AUTOSAR XML (schema 4-2-2)
package /ARPackage_0
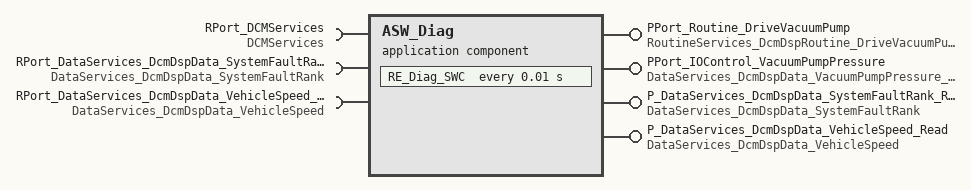
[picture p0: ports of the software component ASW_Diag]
  application sw component type ASW_Diag
    provide port PPort_Routine_DriveVacuumPump: provided-interface=RoutineServices_DcmDspRoutine_DriveVacuumPump
    require port RPort_DCMServices: required-interface=DCMServices
    provide port PPort_IOControl_VacuumPumpPressure: provided-interface=DataServices_DcmDspData_VacuumPumpPressure_1100
    provide port P_DataServices_DcmDspData_SystemFaultRank_Read: provided-interface=DataServices_DcmDspData_SystemFaultRank
    provide port P_DataServices_DcmDspData_VehicleSpeed_Read: provided-interface=DataServices_DcmDspData_VehicleSpeed
    require port RPort_DataServices_DcmDspData_SystemFaultRank_Write: required-interface=DataServices_DcmDspData_SystemFaultRank
    require port RPort_DataServices_DcmDspData_VehicleSpeed_Write: required-interface=DataServices_DcmDspData_VehicleSpeed
    behavior IB_Diag_SWC: data-type-mapping=[DTS_DcmDiagnosticSessionControl, ComMModeMapping, DTS_DcmEcuReset]
      timing event TE_Diag_SWC: start-on-event=RE_Diag_SWC, period=0.01
      8 x operation invoked event:
        OIE_IOControl_VacuumPumpPressure_ReadData: start-on-event=Diag_IOControl_VacuumPumpPressure_ReadData, operation=PPort_IOControl_VacuumPumpPressure.ReadData
        OIE_IOControl_VacuumPumpPressure_returnControlToECU: start-on-event=Diag_IOControl_VacuumPumpPressure_returnControlToECU, operation=PPort_IOControl_VacuumPumpPressure.ReturnControlToECU
        OIE_IOControl_VacuumPumpPressure_resetToDefault: start-on-event=Diag_IOControl_VacuumPumpPressure_resetToDefault, operation=PPort_IOControl_VacuumPumpPressure.ResetToDefault
        OIE_IOControl_VacuumPumpPressure_freezeCurrentState: start-on-event=Diag_IOControl_VacuumPumpPressure_freezeCurrentState, operation=PPort_IOControl_VacuumPumpPressure.FreezeCurrentState
        OIE_IOControl_VacuumPumpPressure_shortTermAdjustment: start-on-event=Diag_IOControl_VacuumPumpPressure_shortTermAdjustment, operation=PPort_IOControl_VacuumPumpPressure.ShortTermAdjustment
        OIE_RoutineServices_DriveVacuumPump_Start: start-on-event=Diag_RoutineServices_DriveVacuumPump_Start, operation=PPort_Routine_DriveVacuumPump.Start
        OIE_RoutineServices_DriveVacuumPump_Stop: start-on-event=Diag_RoutineServices_DriveVacuumPump_Stop, operation=PPort_Routine_DriveVacuumPump.Stop
        OIE_RoutineServices_DriveVacuumPump_RequestRoutineResults: start-on-event=Diag_RoutineServices_DriveVacuumPump_RequestRoutineResults, operation=PPort_Routine_DriveVacuumPump.RequestResults
      9 x runnable:
        RE_Diag_SWC: symbol=RE_Diag_SWC_func
          data-receive-point-by-arguments:
            access DcmDspData_SystemFaultRank_Read: accessed-variable=RPort_DataServices_DcmDspData_SystemFaultRank_Write.Data
            access DcmDspData_VehicleSpeed_Read: accessed-variable=RPort_DataServices_DcmDspData_VehicleSpeed_Write.Data
          data-send-points:
            access DcmDspData_SystemFaultRank_Write: accessed-variable=P_DataServices_DcmDspData_SystemFaultRank_Read.Data
            access DcmDspData_VehicleSpeed_Write: accessed-variable=P_DataServices_DcmDspData_VehicleSpeed_Read.Data
        Diag_IOControl_VacuumPumpPressure_returnControlToECU: symbol=Diag_IOControl_VacuumPumpPressure_returnControlToECU_func
        Diag_IOControl_VacuumPumpPressure_resetToDefault: symbol=Diag_IOControl_VacuumPumpPressure_resetToDefault_func
        Diag_IOControl_VacuumPumpPressure_freezeCurrentState: symbol=Diag_IOControl_VacuumPumpPressure_freezeCurrentState_func
        Diag_IOControl_VacuumPumpPressure_shortTermAdjustment: symbol=Diag_IOControl_VacuumPumpPressure_shortTermAdjustment_func
        Diag_IOControl_VacuumPumpPressure_ReadData: symbol=Diag_IOControl_VacuumPumpPressure_ReadData_func
        Diag_RoutineServices_DriveVacuumPump_Start: symbol=Diag_RoutineServices_DriveVacuumPump_Start_func
        Diag_RoutineServices_DriveVacuumPump_Stop: symbol=Diag_RoutineServices_DriveVacuumPump_Stop_func
        Diag_RoutineServices_DriveVacuumPump_RequestRoutineResults: symbol=Diag_RoutineServices_DriveVacuumPump_RequestRoutineResults_func
